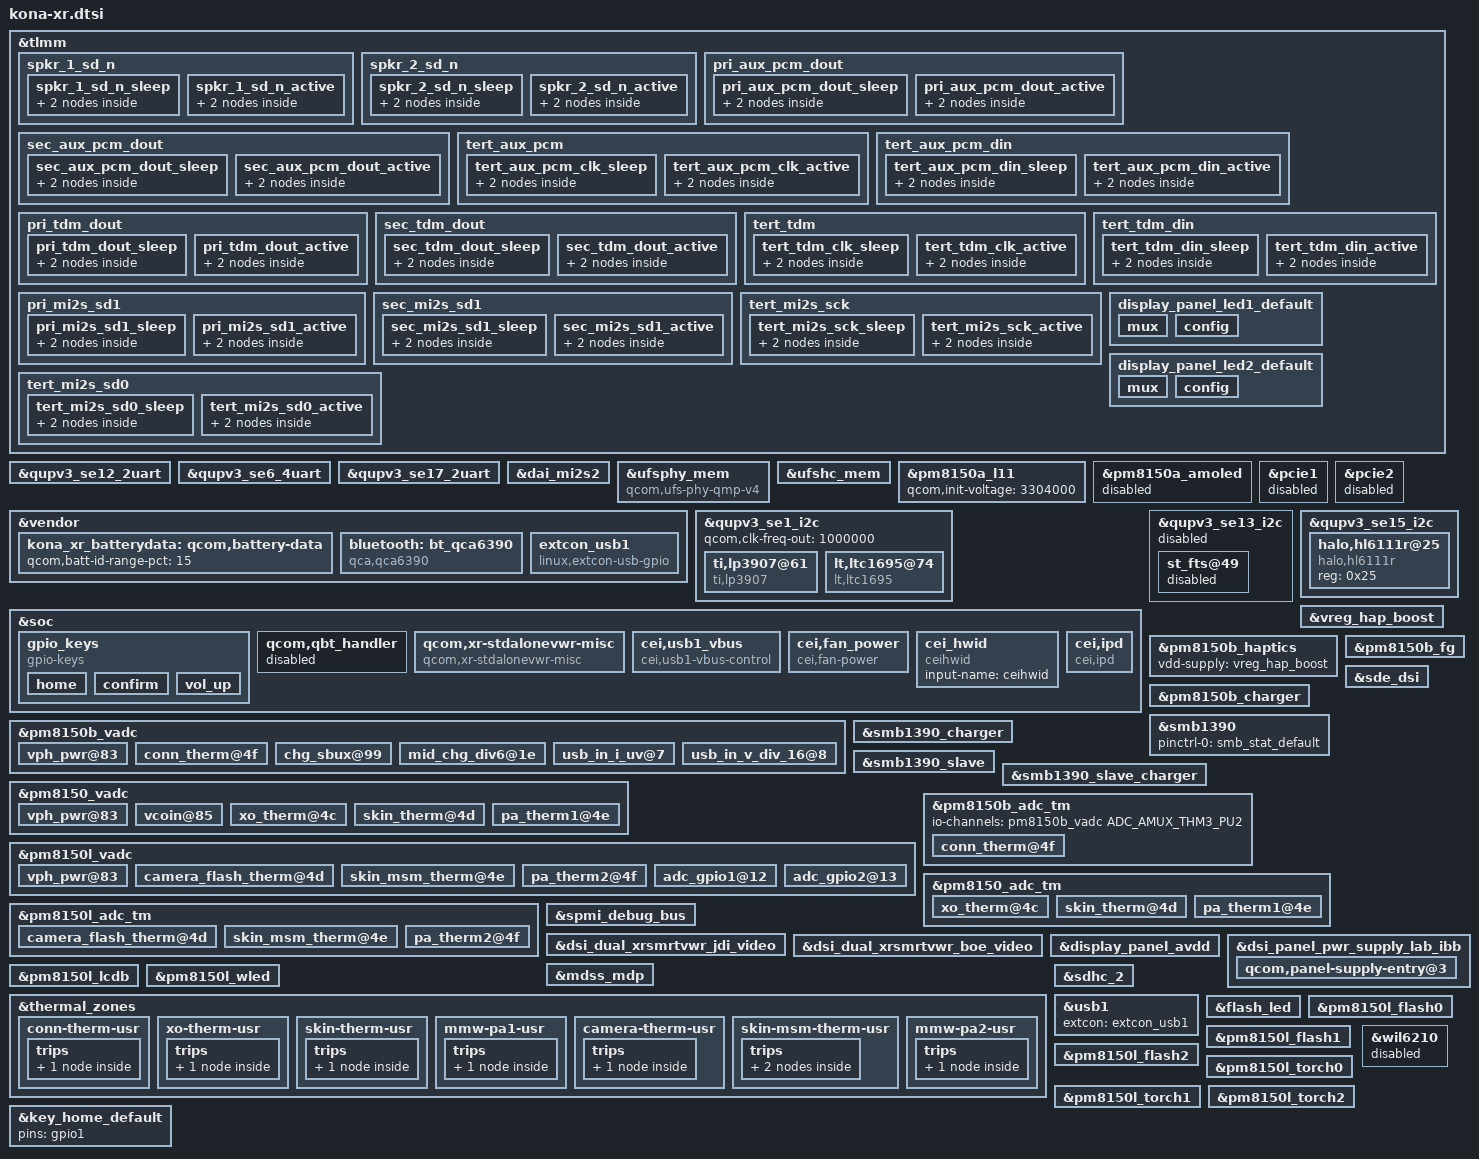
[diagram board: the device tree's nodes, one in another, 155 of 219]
#include <dt-bindings/gpio/gpio.h>
#include <dt-bindings/input/input.h>


#include "kona-pmic-overlay.dtsi"
#include "kona-sde-display.dtsi"
#include "kona-audio-overlay.dtsi"
#include "kona-thermal-overlay.dtsi"
#include "kona-xr-pinctrl-overlay.dtsi"
#include "camera/kona-camera-sensor-xr.dtsi"

&tlmm {
	spkr_1_sd_n {
		spkr_1_sd_n_sleep: spkr_1_sd_n_sleep {
			mux {
				pins = "gpio127";
				function = "gpio";
			};

			config {
				pins = "gpio127";
				drive-strength = <2>;   /* 2 mA */
				bias-pull-down;
				input-enable;
			};
		};

		spkr_1_sd_n_active: spkr_1_sd_n_active {
			mux {
				pins = "gpio127";
				function = "gpio";
			};

			config {
				pins = "gpio127";
				drive-strength = <16>;   /* 16 mA */
				bias-disable;
				output-high;
			};
		};
	};

	spkr_2_sd_n {
		spkr_2_sd_n_sleep: spkr_2_sd_n_sleep {
			mux {
				pins = "gpio129";
				function = "gpio";
			};

			config {
				pins = "gpio129";
				drive-strength = <2>;   /* 2 mA */
				bias-pull-down;
				input-enable;
			};
		};

		spkr_2_sd_n_active: spkr_2_sd_n_active {
			mux {
				pins = "gpio129";
				function = "gpio";
			};

			config {
				pins = "gpio129";
				drive-strength = <16>;   /* 16 mA */
				bias-disable;
				output-high;
			};
		};
	};

	pri_aux_pcm_dout {
		pri_aux_pcm_dout_sleep: pri_aux_pcm_dout_sleep {
			mux {
				pins = "gpio7";
				function = "gpio";
			};

			config {
				pins = "gpio7";
				drive-strength = <2>;   /* 2 mA */
				bias-pull-down;         /* PULL DOWN */
				input-enable;
			};
		};

		pri_aux_pcm_dout_active: pri_aux_pcm_dout_active {
			mux {
				pins = "gpio7";
				function = "mi2s0_data1";
			};

			config {
				pins = "gpio7";
				drive-strength = <8>;   /* 8 mA */
				bias-disable;           /* NO PULL */
			};
		};
	};

	sec_aux_pcm_dout {
		sec_aux_pcm_dout_sleep: sec_aux_pcm_dout_sleep {
			mux {
				pins = "gpio6";
				function = "gpio";
			};

			config {
				pins = "gpio6";
				drive-strength = <2>;   /* 2 mA */
				bias-pull-down;         /* PULL DOWN */
				input-enable;
			};
		};

		sec_aux_pcm_dout_active: sec_aux_pcm_dout_active {
			mux {
				pins = "gpio6";
				function = "mi2s0_data1";
			};

			config {
				pins = "gpio6";
				drive-strength = <8>;   /* 8 mA */
				bias-disable;           /* NO PULL */
			};
		};
	};

	tert_aux_pcm {
		tert_aux_pcm_clk_sleep: tert_aux_pcm_clk_sleep {
			mux {
				pins = "gpio9";
				function = "gpio";
			};

			config {
				pins = "gpio9";
				drive-strength = <2>;   /* 2 mA */
				bias-pull-down;         /* PULL DOWN */
				input-enable;
			};
		};

		tert_aux_pcm_clk_active: tert_aux_pcm_clk_active {
			mux {
				pins = "gpio9";
				function = "mi2s2_sck";
			};

			config {
				pins = "gpio9";
				drive-strength = <8>;   /* 8 mA */
				bias-disable;           /* NO PULL */
				output-high;
			};
		};
	};

	tert_aux_pcm_din {
		tert_aux_pcm_din_sleep: tert_aux_pcm_din_sleep {
			mux {
				pins = "gpio8";
				function = "gpio";
			};

			config {
				pins = "gpio8";
				drive-strength = <2>;   /* 2 mA */
				bias-pull-down;         /* PULL DOWN */
				input-enable;
			};
		};

		tert_aux_pcm_din_active: tert_aux_pcm_din_active {
			mux {
				pins = "gpio8";
				function = "mi2s2_data0";
			};

			config {
				pins = "gpio8";
				drive-strength = <8>;   /* 8 mA */
				bias-disable;           /* NO PULL */
			};
		};
	};

	pri_tdm_dout {
		pri_tdm_dout_sleep: pri_tdm_dout_sleep {
			mux {
				pins = "gpio7";
				function = "gpio";
			};

			config {
				pins = "gpio7";
				drive-strength = <2>;   /* 2 mA */
				bias-pull-down;         /* PULL DOWN */
				input-enable;
			};
		};

		pri_tdm_dout_active: pri_tdm_dout_active {
			mux {
				pins = "gpio7";
				function = "mi2s0_data1";
			};

			config {
				pins = "gpio7";
				drive-strength = <8>;   /* 8 mA */
				bias-disable;           /* NO PULL */
			};
		};
	};

	sec_tdm_dout {
		sec_tdm_dout_sleep: sec_tdm_dout_sleep {
			mux {
				pins = "gpio6";
				function = "gpio";
			};

			config {
				pins = "gpio6";
				drive-strength = <2>;   /* 2 mA */
				bias-pull-down;         /* PULL DOWN */
				input-enable;
			};
		};

		sec_tdm_dout_active: sec_tdm_dout_active {
			mux {
				pins = "gpio6";
				function = "mi2s1_data1";
			};

			config {
				pins = "gpio6";
				drive-strength = <8>;   /* 8 mA */
				bias-disable;           /* NO PULL */
			};
		};
	};

	tert_tdm {
		tert_tdm_clk_sleep: tert_tdm_clk_sleep {
			mux {
				pins = "gpio9";
				function = "gpio";
			};

			config {
				pins = "gpio9";
				drive-strength = <2>;   /* 2 mA */
				bias-pull-down;         /* PULL DOWN */
				input-enable;
			};
		};

		tert_tdm_clk_active: tert_tdm_clk_active {
			mux {
				pins = "gpio9";
				function = "mi2s2_sck";
			};

			config {
				pins = "gpio9";
				drive-strength = <8>;   /* 8 mA */
				bias-disable;           /* NO PULL */
				output-high;
			};
		};
	};

	tert_tdm_din {
		tert_tdm_din_sleep: tert_tdm_din_sleep {
			mux {
				pins = "gpio8";
				function = "gpio";
			};

			config {
				pins = "gpio8";
				drive-strength = <2>;   /* 2 mA */
				bias-pull-down;         /* PULL DOWN */
				input-enable;
			};
		};

		tert_tdm_din_active: tert_tdm_din_active {
			mux {
				pins = "gpio8";
				function = "mi2s2_data0";
			};

			config {
				pins = "gpio8";
				drive-strength = <8>;   /* 8 mA */
				bias-disable;           /* NO PULL */
			};
		};
	};

	pri_mi2s_sd1 {
		pri_mi2s_sd1_sleep: pri_mi2s_sd1_sleep {
			mux {
				pins = "gpio7";
				function = "gpio";
			};

			config {
				pins = "gpio7";
				drive-strength = <2>;   /* 2 mA */
				bias-pull-down;         /* PULL DOWN */
				input-enable;
			};
		};

		pri_mi2s_sd1_active: pri_mi2s_sd1_active {
			mux {
				pins = "gpio7";
				function = "mi2s2_data0";
			};

			config {
				pins = "gpio7";
				drive-strength = <8>;   /* 8 mA */
				bias-disable;           /* NO PULL */
				output-high;
			};
		};
	};

	sec_mi2s_sd1 {
		sec_mi2s_sd1_sleep: sec_mi2s_sd1_sleep {
			mux {
				pins = "gpio6";
				function = "gpio";
			};

			config {
				pins = "gpio6";
				drive-strength = <2>;   /* 2 mA */
				bias-pull-down;         /* PULL DOWN */
				input-enable;
			};
		};

		sec_mi2s_sd1_active: sec_mi2s_sd1_active {
			mux {
				pins = "gpio6";
				function = "mi2s1_data1";
			};

			config {
				pins = "gpio6";
				drive-strength = <8>;   /* 8 mA */
				bias-disable;           /* NO PULL */
			};
		};
	};

	tert_mi2s_sck {
		tert_mi2s_sck_sleep: tert_mi2s_sck_sleep {
			mux {
				pins = "gpio9";
				function = "gpio";
			};

			config {
				pins = "gpio9";
				drive-strength = <2>;   /* 2 mA */
				bias-pull-down;         /* PULL DOWN */
				input-enable;
			};
		};

		tert_mi2s_sck_active: tert_mi2s_sck_active {
			mux {
				pins = "gpio9";
				function = "mi2s2_sck";
			};

			config {
				pins = "gpio9";
				drive-strength = <8>;   /* 8 mA */
				bias-disable;           /* NO PULL */
			};
		};
	};

	tert_mi2s_sd0 {
		tert_mi2s_sd0_sleep: tert_mi2s_sd0_sleep {
			mux {
				pins = "gpio8";
				function = "gpio";
			};

			config {
				pins = "gpio8";
				drive-strength = <2>;   /* 2 mA */
				bias-pull-down;         /* PULL DOWN */
				input-enable;
			};
		};

		tert_mi2s_sd0_active: tert_mi2s_sd0_active {
			mux {
				pins = "gpio8";
				function = "mi2s2_data0";
			};

			config {
				pins = "gpio8";
				drive-strength = <8>;   /* 8 mA */
				bias-disable;           /* NO PULL */
			};
		};
	};

	display_panel_led1_default: display_panel_led1_default {
		mux {
			pins = "gpio144";
			function = "gpio";
		};

		config {
			pins = "gpio144";
			drive-strength = <8>;
			bias-disable = <0>;
			output-high;
		};
	};

	display_panel_led2_default: display_panel_led2_default {
		mux {
			pins = "gpio140";
			function = "gpio";
		};

		config {
			pins = "gpio140";
			drive-strength = <8>;
			bias-disable = <0>;
			output-high;
		};
	};

};

&qupv3_se12_2uart {
	status = "ok";
};

&qupv3_se6_4uart {
	status = "ok";
};

&qupv3_se17_2uart {
	status = "ok";
};

&dai_mi2s2 {
	status = "ok";
	qcom,msm-mi2s-tx-lines = <1>;
	pinctrl-names = "default", "sleep";
	pinctrl-0 = <&tert_mi2s_sck_active &tert_mi2s_ws_active
			&tert_mi2s_sd0_active>;
	pinctrl-1 = <&tert_mi2s_sck_sleep &tert_mi2s_ws_sleep
			&tert_mi2s_sd0_sleep>;
};


&ufsphy_mem {
	compatible = "qcom,ufs-phy-qmp-v4";

	vdda-phy-supply = <&pm8150_l5>;
	vdda-phy-always-on;
	vdda-pll-supply = <&pm8150_l9>;
	vdda-phy-max-microamp = <89900>;
	vdda-pll-max-microamp = <18800>;

	status = "ok";
};

&ufshc_mem {
	vdd-hba-supply = <&ufs_phy_gdsc>;
	vdd-hba-fixed-regulator;
	vcc-supply = <&pm8150_l17>;
	vcc-voltage-level = <2504000 2950000>;
	vcc-low-voltage-sup;
	vccq-supply = <&pm8150_l6>;
	vccq2-supply = <&pm8150_s4>;
	vcc-max-microamp = <800000>;
	vccq-max-microamp = <800000>;
	vccq2-max-microamp = <800000>;

	qcom,vddp-ref-clk-supply = <&pm8150_l6>;
	qcom,vddp-ref-clk-max-microamp = <100>;

	status = "ok";
};

&pm8150a_l11 {
	qcom,init-voltage = <3304000>;
};


&vendor {
	kona_xr_batterydata: qcom,battery-data {
		qcom,batt-id-range-pct = <15>;
		#include "lynx-r1-battery.dtsi"
	};
};


&pm8150a_amoled {
	status = "disabled";
};

&qupv3_se1_i2c {
	status = "ok";
	qcom,clk-freq-out = <1000000>;
	#address-cells = <1>;
	#size-cells = <0>;
	/* LP3907 LDO controller for Fan power*/
	ti,lp3907@61 {
		reg=<0x61>;
		compatible = "ti,lp3907";
		input-name = "lp3907";
		enable-gpio = <&tlmm 38 0>;
		enable-mode = <0>;
		ldo1-vol-mv = <2200>;
		ldo2-vol-mv = <2200>;
	};

	/* LTC1695 Voltage controller for Fan power*/
	lt,ltc1695@74 {
		reg=<0x74>;
		compatible = "lt,ltc1695";
		input-name = "ltc1695";

		vreg-3v0-supply = <&pm8150_l10>;
		vreg-3v0-voltage-level = <3000000 3000000>;
		enable-gpio = <&tlmm 38 0>;
		enable-mode = <1>;
		voltage-lvl-default = <0>;
		boost-start-timer-enable = <0>;
	};
};

&pcie1 {
	status = "disabled";
};

&pcie2 {
	status = "disabled";
};

&soc {
	gpio_keys {
		compatible = "gpio-keys";
		label = "gpio-keys";

		pinctrl-names = "default";
		pinctrl-0 = <&key_home_default
			&key_confirm_default
			&key_vol_up_default>;

		home {
			label = "home";
			gpios = <&pm8150_gpios 1 GPIO_ACTIVE_LOW>;
			linux,input-type = <1>;
			linux,code = <KEY_HOME>;
			gpio-key,wakeup;
			debounce-interval = <15>;
			linux,can-disable;
		};

		confirm {
			label = "confirm";
			gpios = <&pm8150_gpios 7 GPIO_ACTIVE_LOW>;
			linux,input-type = <1>;
			linux,code = <KEY_ENTER>;
			gpio-key,wakeup;
			debounce-interval = <15>;
			linux,can-disable;
		};

		vol_up {
			label = "volume_up";
			gpios = <&pm8150_gpios 6 GPIO_ACTIVE_LOW>;
			linux,input-type = <1>;
			linux,code = <KEY_VOLUMEUP>;
			gpio-key,wakeup;
			debounce-interval = <15>;
			linux,can-disable;
		};
	};

	qcom,qbt_handler {
		status = "disabled";
	};

	qcom,xr-stdalonevwr-misc {
		status ="ok";
		compatible = "qcom,xr-stdalonevwr-misc";
		/* IMU CLK Enable PM8150 GPIO 3 */
		pinctrl-names = "default", "sleep";
		pinctrl-0 = <&imu_clkin_default>;
		pinctrl-1 = <&imu_clkin_sleep>;

	};

	cei,usb1_vbus {
		compatible = "cei,usb1-vbus-control";
		usb1_vbus-gpio = <&tlmm 48 0>;
		usb1_vbus-enable = <0>;
	};

	cei,fan_power {
		compatible = "cei,fan-power";
		fan_power-gpio = <&tlmm 38 0>;
		fan_power-enable = <0>;
	};

	cei_hwid {
		compatible = "ceihwid";
		input-name = "ceihwid";
		status = "ok";
	};
	
	cei,ipd {
		compatible = "cei,ipd";
		io-channels = <&pm8150l_vadc ADC_GPIO1>,
					<&pm8150l_vadc ADC_GPIO2>;
		io-channel-names = "ipd_left",
						   "ipd_right";
		biase_voltage-gpio = <&tlmm 64 0>;
	};
};

&qupv3_se13_i2c {
	#address-cells = <1>;
	#size-cells = <0>;

	status = "disabled";

	st_fts@49 {
		status = "disabled";
	};
};

&qupv3_se15_i2c {
	#address-cells = <1>;
	#size-cells = <0>;

	halo,hl6111r@25 {
		compatible = "halo,hl6111r";
		reg = <0x25>;
		status = "disabled";
	};
};

&vendor {
	bluetooth: bt_qca6390 {
		compatible = "qca,qca6390";
		pinctrl-names = "default";
		pinctrl-0 = <&bt_en_sleep>;
		qca,bt-reset-gpio = <&tlmm 21 0>; /* BT_EN */
		qca,bt-sw-ctrl-gpio = <&tlmm 124 0>; /* SW_CTRL */
		qca,bt-vdd-aon-supply = <&pm8150_s6>;
		qca,bt-vdd-dig-supply = <&pm8009_s2>;
		qca,bt-vdd-rfa1-supply = <&pm8150_s5>;
		qca,bt-vdd-rfa2-supply = <&pm8150a_s8>;
		qca,bt-vdd-asd-supply = <&pm8150_l16>;

		qca,bt-vdd-aon-voltage-level = <950000 950000>;
		qca,bt-vdd-dig-voltage-level = <950000 952000>;
		qca,bt-vdd-rfa1-voltage-level = <1900000 1900000>;
		qca,bt-vdd-rfa2-voltage-level = <1350000 1350000>;
		qca,bt-vdd-asd-voltage-level = <3024000 3304000>;

		qca,bt-vdd-asd-current-level = <10000>;
	};

	extcon_usb1: extcon_usb1 {
		compatible = "linux,extcon-usb-gpio";
		vbus-gpio = <&pm8150_gpios 10 GPIO_ACTIVE_HIGH>;
		id-gpio = <&tlmm 91 GPIO_ACTIVE_HIGH>;
		vbus-out-gpio = <&pm8150_gpios 9 GPIO_ACTIVE_HIGH>;

		pinctrl-names = "default";
		pinctrl-0 = <&usb2_vbus_det_default
			     &usb2_id_det_default
			     &usb2_vbus_boost_default>;
	};
};

&vreg_hap_boost {
	status = "ok";
};

&pm8150b_haptics {
	vdd-supply = <&vreg_hap_boost>;
};

&pm8150b_vadc {
	#address-cells = <1>;
	#size-cells = <0>;

	vph_pwr@83 {
		reg = <ADC_VPH_PWR>;
		label = "vph_pwr";
		qcom,pre-scaling = <1 3>;
	};

	conn_therm@4f {
		reg = <ADC_AMUX_THM3_PU2>;
		label = "conn_therm";
		qcom,ratiometric;
		qcom,hw-settle-time = <200>;
		qcom,pre-scaling = <1 1>;
	};

	chg_sbux@99 {
		reg = <ADC_SBUx>;
		label = "chg_sbux";
		qcom,pre-scaling = <1 3>;
	};

	mid_chg_div6@1e {
		reg = <ADC_MID_CHG_DIV6>;
		label = "chg_mid";
		qcom,pre-scaling = <1 6>;
	};

	usb_in_i_uv@7 {
		reg = <ADC_USB_IN_I>;
		label = "usb_in_i_uv";
		qcom,pre-scaling = <1 1>;
	};

	usb_in_v_div_16@8 {
		reg = <ADC_USB_IN_V_16>;
		label = "usb_in_v_div_16";
		qcom,pre-scaling = <1 16>;
	};
};

&pm8150b_charger {
	status = "ok";
	qcom,sec-charger-config = <1>;
	qcom,auto-recharge-soc = <98>;
	io-channels = <&pm8150b_vadc ADC_MID_CHG_DIV6>,
		      <&pm8150b_vadc ADC_USB_IN_I>,
		      <&pm8150b_vadc ADC_SBUx>,
		      <&pm8150b_vadc ADC_VPH_PWR>,
		      <&pm8150b_vadc ADC_CHG_TEMP>;
	io-channel-names = "mid_voltage",
			   "usb_in_current",
			   "sbux_res",
			   "vph_voltage",
			   "chg_temp";
	qcom,battery-data = <&kona_xr_batterydata>;
	qcom,sw-jeita-enable;
	qcom,wd-bark-time-secs = <16>;
	qcom,suspend-input-on-debug-batt;
	qcom,fcc-stepping-enable;

	qcom,fcc-max-ua = <3400000>;
	qcom,fv-max-uv = <4200000>;
	qcom,chg-term-base-current-ma = <200>;
	qcom,chg-term-current-ma = <250>;
};

&pm8150b_fg {
	status = "ok";
	qcom,battery-data = <&kona_xr_batterydata>;
	qcom,hold-soc-while-full;
	qcom,linearize-soc;
	qcom,five-pin-battery;
	qcom,cl-wt-enable;
	qcom,soc-scale-mode-en;
	/* ESR fast calibration */
	qcom,fg-esr-timer-chg-fast = <0 7>;
	qcom,fg-esr-timer-dischg-fast = <0 7>;
	qcom,fg-esr-timer-chg-slow = <0 96>;
	qcom,fg-esr-timer-dischg-slow = <0 96>;
	qcom,fg-esr-cal-soc-thresh = <26 230>;
	qcom,fg-esr-cal-temp-thresh = <10 40>;

	qcom,fg-cutoff-voltage = <3200>;
	qcom,fg-sys-term-current = <(-250)>;
};

&qupv3_se15_i2c {
	#address-cells = <1>;
	#size-cells = <0>;
#include "smb1390.dtsi"

	halo,hl6111r@25 {
		compatible = "halo,hl6111r";
		reg = <0x25>;
		status = "ok";
	};
};

&smb1390 {
	pinctrl-names = "default";
	pinctrl-0 = <&smb_stat_default>;
	status = "ok";
};

&smb1390_charger {
	io-channels = <&pm8150b_vadc ADC_AMUX_THM2>;
	io-channel-names = "cp_die_temp";
	qcom,parallel-output-mode = <2>;
	qcom,parallel-input-mode = <3>;
	qcom,min-ilim-ua = <750000>;
	status = "ok";
};

&smb1390_slave {
	status = "ok";
};

&smb1390_slave_charger {
	status = "ok";
};

&pm8150_vadc {
	#address-cells = <1>;
	#size-cells = <0>;

	vph_pwr@83 {
		reg = <ADC_VPH_PWR>;
		label = "vph_pwr";
		qcom,pre-scaling = <1 3>;
	};

	vcoin@85 {
		reg = <ADC_VCOIN>;
		label = "vcoin";
		qcom,pre-scaling = <1 3>;
	};

	xo_therm@4c {
		reg = <ADC_XO_THERM_PU2>;
		label = "xo_therm";
		qcom,ratiometric;
		qcom,hw-settle-time = <200>;
		qcom,pre-scaling = <1 1>;
	};

	skin_therm@4d {
		reg = <ADC_AMUX_THM1_PU2>;
		label = "skin_therm";
		qcom,ratiometric;
		qcom,hw-settle-time = <200>;
		qcom,pre-scaling = <1 1>;
	};

	pa_therm1@4e {
		reg = <ADC_AMUX_THM2_PU2>;
		label = "pa_therm1";
		qcom,ratiometric;
		qcom,hw-settle-time = <200>;
		qcom,pre-scaling = <1 1>;
	};
};

&pm8150l_vadc {
	#address-cells = <1>;
	#size-cells = <0>;

	vph_pwr@83 {
		reg = <ADC_VPH_PWR>;
		label = "vph_pwr";
		qcom,pre-scaling = <1 3>;
	};

	camera_flash_therm@4d {
		reg = <ADC_AMUX_THM1_PU2>;
		label = "camera_flash_therm";
		qcom,ratiometric;
		qcom,hw-settle-time = <200>;
		qcom,pre-scaling = <1 1>;
	};

	skin_msm_therm@4e {
		reg = <ADC_AMUX_THM2_PU2>;
		label = "skin_msm_therm";
		qcom,ratiometric;
		qcom,hw-settle-time = <200>;
		qcom,pre-scaling = <1 1>;
	};

	pa_therm2@4f {
		reg = <ADC_AMUX_THM3_PU2>;
		label = "pa_therm2";
		qcom,ratiometric;
		qcom,hw-settle-time = <200>;
		qcom,pre-scaling = <1 1>;
	};

	adc_gpio1@12 {
		reg = <ADC_GPIO1>;
		label = "adc_gpio1";
		qcom,pre-scaling = <1 1>;
	};

	adc_gpio2@13 {
		reg = <ADC_GPIO2>;
		label = "adc_gpio2";
		qcom,pre-scaling = <1 1>;
	};
};

&pm8150b_adc_tm {
	#address-cells = <1>;
	#size-cells = <0>;

	io-channels = <&pm8150b_vadc ADC_AMUX_THM3_PU2>;

	conn_therm@4f {
		reg = <ADC_AMUX_THM3_PU2>;
		qcom,ratiometric;
		qcom,hw-settle-time = <200>;
	};
};

&pm8150_adc_tm {
	#address-cells = <1>;
	#size-cells = <0>;

	io-channels = <&pm8150_vadc ADC_XO_THERM_PU2>,
			<&pm8150_vadc ADC_AMUX_THM1_PU2>,
			<&pm8150_vadc ADC_AMUX_THM2_PU2>;

	xo_therm@4c {
		reg = <ADC_XO_THERM_PU2>;
		qcom,ratiometric;
		qcom,hw-settle-time = <200>;
	};

	skin_therm@4d {
		reg = <ADC_AMUX_THM1_PU2>;
		qcom,ratiometric;
		qcom,hw-settle-time = <200>;
	};

	pa_therm1@4e {
		reg = <ADC_AMUX_THM2_PU2>;
		qcom,ratiometric;
		qcom,hw-settle-time = <200>;
	};
};

&pm8150l_adc_tm {
	#address-cells = <1>;
	#size-cells = <0>;

	camera_flash_therm@4d {
		reg = <ADC_AMUX_THM1_PU2>;
		qcom,ratiometric;
		qcom,hw-settle-time = <200>;
	};

	skin_msm_therm@4e {
		reg = <ADC_AMUX_THM2_PU2>;
		qcom,ratiometric;
		qcom,hw-settle-time = <200>;
	};

	pa_therm2@4f {
		reg = <ADC_AMUX_THM3_PU2>;
		qcom,ratiometric;
		qcom,hw-settle-time = <200>;
	};
};

&spmi_debug_bus {
	status = "ok";
};

&dsi_dual_xrsmrtvwr_jdi_video {
	qcom,panel-supply-entries = <&dsi_panel_pwr_supply_lab_ibb>;
	qcom,mdss-dsi-bl-pmic-control-type = "bl_ctrl_external";
	qcom,mdss-dsi-bl-min-level = <1>;
	qcom,mdss-dsi-bl-max-level = <4095>;
	qcom,mdss-brightness-max-level = <255>;
	qcom,platform-reset-gpio = <&tlmm 75 0>;
	qcom,platform-te-gpio = <&tlmm 66 0>;

	qcom,platform-bklight-en-gpio = <&tlmm 133 0>;
	qcom,5v-boost-gpio = <&tlmm 134 0>;
	/delete-property/ qcom,platform-en-gpio;
};

&dsi_dual_xrsmrtvwr_boe_video {
	qcom,panel-supply-entries = <&dsi_panel_pwr_supply_lab_ibb>;
	qcom,mdss-dsi-bl-pmic-control-type = "bl_ctrl_external";
	qcom,mdss-dsi-bl-min-level = <1>;
	qcom,mdss-dsi-bl-max-level = <4095>;
	qcom,mdss-brightness-max-level = <255>;
	qcom,platform-reset-gpio = <&tlmm 75 0>;
	qcom,platform-te-gpio = <&tlmm 66 0>;

	qcom,platform-bklight-en-gpio = <&tlmm 133 0>;
	qcom,5v-boost-gpio = <&tlmm 134 0>;
	/delete-property/ qcom,platform-en-gpio;
};

&sde_dsi {
	avdd-supply = <&display_panel_avdd>;
	lab-supply = <&lcdb_ldo_vreg>;
	ibb-supply = <&lcdb_ncp_vreg>;
	qcom,dsi-default-panel = <&dsi_dual_xrsmrtvwr_jdi_video>;
};

&display_panel_avdd {
	display_panel_led1_gpio = <&tlmm 144 0>;
	display_panel_led2_gpio = <&tlmm 140 0>;
	enable-active-high;
	regulator-boot-on;
	pinctrl-names = "default";
	pinctrl-0 = <&display_panel_led1_default
			 &display_panel_led2_default>;
};

&dsi_panel_pwr_supply_lab_ibb {
	qcom,panel-supply-entry@3 {
		reg = <1>;
		qcom,supply-name = "avdd";
		qcom,supply-min-voltage = <4600000>;
		qcom,supply-max-voltage = <6000000>;
		qcom,supply-enable-load = <100000>;
		qcom,supply-disable-load = <100>;
	};
};

&mdss_mdp {
	connectors = <&sde_dp &sde_dsi &sde_dsi1 &sde_rscc>;
};

&pm8150l_lcdb {
	status = "ok";
};

&pm8150l_wled {
	status = "ok";
};

&thermal_zones {
	conn-therm-usr {
		polling-delay-passive = <0>;
		polling-delay = <0>;
		thermal-governor = "user_space";
		thermal-sensors = <&pm8150b_adc_tm ADC_AMUX_THM3_PU2>;
		wake-capable-sensor;
		trips {
			active-config0 {
				temperature = <125000>;
				hysteresis = <1000>;
				type = "passive";
			};
		};
	};

	xo-therm-usr {
		polling-delay-passive = <0>;
		polling-delay = <0>;
		thermal-governor = "user_space";
		thermal-sensors = <&pm8150_adc_tm ADC_XO_THERM_PU2>;
		wake-capable-sensor;
		trips {
			active-config0 {
				temperature = <125000>;
				hysteresis = <1000>;
				type = "passive";
			};
		};
	};

	skin-therm-usr {
		polling-delay-passive = <0>;
		polling-delay = <0>;
		thermal-governor = "user_space";
		thermal-sensors = <&pm8150_adc_tm ADC_AMUX_THM1_PU2>;
		wake-capable-sensor;
		trips {
			active-config0 {
				temperature = <125000>;
				hysteresis = <1000>;
				type = "passive";
			};
		};
	};

	mmw-pa1-usr {
		polling-delay-passive = <0>;
		polling-delay = <0>;
		thermal-governor = "user_space";
		thermal-sensors = <&pm8150_adc_tm ADC_AMUX_THM2_PU2>;
		wake-capable-sensor;
		trips {
			active-config0 {
				temperature = <125000>;
				hysteresis = <1000>;
				type = "passive";
			};
		};
	};

	camera-therm-usr {
		polling-delay-passive = <0>;
		polling-delay = <0>;
		thermal-governor = "user_space";
		thermal-sensors = <&pm8150l_adc_tm ADC_AMUX_THM1_PU2>;
		wake-capable-sensor;
		trips {
			active-config0 {
				temperature = <125000>;
				hysteresis = <1000>;
				type = "passive";
			};
		};
	};

	skin-msm-therm-usr {
		polling-delay-passive = <0>;
		polling-delay = <0>;
		thermal-governor = "user_space";
		thermal-sensors = <&pm8150l_adc_tm ADC_AMUX_THM2_PU2>;
		wake-capable-sensor;
		trips {
			active-config0 {
				temperature = <125000>;
				hysteresis = <1000>;
				type = "passive";
			};

			active-config1 {
				temperature = <125000>;
				hysteresis = <1000>;
				type = "passive";
			};
		};
	};

	mmw-pa2-usr {
		polling-delay-passive = <0>;
		polling-delay = <0>;
		thermal-governor = "user_space";
		thermal-sensors = <&pm8150l_adc_tm ADC_AMUX_THM3_PU2>;
		wake-capable-sensor;
		trips {
			active-config0 {
				temperature = <125000>;
				hysteresis = <1000>;
				type = "passive";
			};
		};
	};
};

&sdhc_2 {
	vdd-supply = <&pm8150a_l9>;
	qcom,vdd-voltage-level = <2950000 2960000>;
	qcom,vdd-current-level = <200 800000>;

	vdd-io-supply = <&pm8150a_l6>;
	qcom,vdd-io-voltage-level = <1808000 2960000>;
	qcom,vdd-io-current-level = <200 22000>;

	pinctrl-names = "active", "sleep";
	pinctrl-0 = <&sdc2_clk_on  &sdc2_cmd_on &sdc2_data_on &storage_cd>;
	pinctrl-1 = <&sdc2_clk_off &sdc2_cmd_off &sdc2_data_off &storage_cd>;

	cd-gpios = <&tlmm 77 GPIO_ACTIVE_LOW>;

	status = "ok";
};

&usb1 {
	extcon = <&extcon_usb1>;
};

&flash_led {
	qcom,hw-strobe-option = <0>;
	qcom,strobe-sel = <1>;
};

&pm8150l_flash0 {
	qcom,hw-strobe-option = <0>;
	qcom,strobe-sel = <0>;
};

&pm8150l_flash1 {
	qcom,hw-strobe-option = <0>;
	qcom,strobe-sel = <0>;
};

&pm8150l_flash2 {
	qcom,hw-strobe-option = <0>;
	qcom,strobe-sel = <0>;
};

&pm8150l_torch0 {
	qcom,hw-strobe-option = <0>;
	qcom,strobe-sel = <0>;
};

&pm8150l_torch1 {
	qcom,hw-strobe-option = <0>;
	qcom,strobe-sel = <0>;
};

&pm8150l_torch2 {
	qcom,hw-strobe-option = <0>;
	qcom,strobe-sel = <0>;
};

&wil6210 {
	status = "disabled";
};

&key_home_default {
	pins = "gpio1";
};
